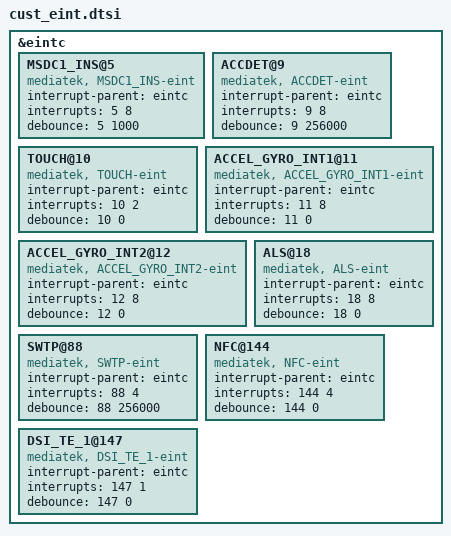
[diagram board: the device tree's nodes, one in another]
/*
 * Generated by MTK SP DrvGen Version 03.13.6 for MT6753. Copyright MediaTek Inc. (C) 2013.
 * Sat Sep 03 19:32:09 2016
 * Do Not Modify the File.
 */

/*************************
 * EINT DTSI File
*************************/

&eintc {
	MSDC1_INS@5 {
		compatible = "mediatek, MSDC1_INS-eint";
		interrupt-parent = <&eintc>;
		interrupts = <5 8>;
		debounce = <5 1000>;
	};

	ACCDET@9 {
		compatible = "mediatek, ACCDET-eint";
		interrupt-parent = <&eintc>;
		interrupts = <9 8>;
		debounce = <9 256000>;
	};

	TOUCH@10 {
		compatible = "mediatek, TOUCH-eint";
		interrupt-parent = <&eintc>;
		interrupts = <10 2>;
		debounce = <10 0>;
	};

	ACCEL_GYRO_INT1@11 {
		compatible = "mediatek, ACCEL_GYRO_INT1-eint";
		interrupt-parent = <&eintc>;
		interrupts = <11 8>;
		debounce = <11 0>;
	};

	ACCEL_GYRO_INT2@12 {
		compatible = "mediatek, ACCEL_GYRO_INT2-eint";
		interrupt-parent = <&eintc>;
		interrupts = <12 8>;
		debounce = <12 0>;
	};

	ALS@18 {
		compatible = "mediatek, ALS-eint";
		interrupt-parent = <&eintc>;
		interrupts = <18 8>;
		debounce = <18 0>;
	};

	SWTP@88 {
		compatible = "mediatek, SWTP-eint";
		interrupt-parent = <&eintc>;
		interrupts = <88 4>;
		debounce = <88 256000>;
	};

	NFC@144 {
		compatible = "mediatek, NFC-eint";
		interrupt-parent = <&eintc>;
		interrupts = <144 4>;
		debounce = <144 0>;
	};

	DSI_TE_1@147 {
		compatible = "mediatek, DSI_TE_1-eint";
		interrupt-parent = <&eintc>;
		interrupts = <147 1>;
		debounce = <147 0>;
	};

};
